AUTOSAR XML (schema 4-2-1)
package /MICROSAR/Dcm_swc
  mode declaration group DcmControlDtcSetting: category=EXPLICIT_ORDER, initial-mode=ENABLEDTCSETTING, on-transition-value=2
    mode ENABLEDTCSETTING: value=0
    mode DISABLEDTCSETTING: value=1
  mode declaration group DcmEcuReset: category=EXPLICIT_ORDER, initial-mode=NONE, on-transition-value=7
    7 x mode:
      NONE: value=0
      HARD: value=1
      KEYONOFF: value=2
      SOFT: value=3
      JUMPTOBOOTLOADER: value=4
      JUMPTOSYSSUPPLIERBOOTLOADER: value=5
      EXECUTE: value=6
  mode declaration group DcmDiagnosticSessionControl: category=EXPLICIT_ORDER, initial-mode=DEFAULT_SESSION, on-transition-value=255
    mode DEFAULT_SESSION: value=1
    mode PROGRAMMING_SESSION: value=2
    mode EXTENDED_SESSION: value=3
  data type mapping set DcmMappingSet  # Contains mapping for ModeDeclarationGroups which are provided by Dcm.
    mode-request-type-maps:
      implementation-data-type=Dcm_ControlDtcSettingType, mode-group=DcmControlDtcSetting
      implementation-data-type=Dcm_EcuResetType, mode-group=DcmEcuReset
      implementation-data-type=Dcm_DiagnosticSessionControlType, mode-group=DcmDiagnosticSessionControl
package /MICROSAR/Dcm_swc/DataTypes
  13 x impl type:
    Dcm_ConfirmationStatusType: compu {0=DCM_RES_POS_OK, 1=DCM_RES_POS_NOT_OK, 2=DCM_RES_NEG_OK, 3=DCM_RES_NEG_NOT_OK}, range raw 0..3, implementation-data-type=uint8
    Dcm_OpStatusType: compu {0=DCM_INITIAL, 1=DCM_PENDING, 2=DCM_CANCEL, 3=DCM_FORCE_RCRRP_OK, 64=DCM_FORCE_RCRRP_NOT_OK}, range raw 0..64, implementation-data-type=uint8
    Dcm_NegativeResponseCodeType:
      compu {0=DCM_E_POSITIVERESPONSE, 16=DCM_E_GENERALREJECT, 17=DCM_E_SERVICENOTSUPPORTED, 18=DCM_E_SUBFUNCTIONNOTSUPPORTED, 19=DCM_E_INCORRECTMESSAGELENGTHORINVALIDFORMAT, 20=DCM_E_RESPONSETOOLONG, 33=DCM_E_BUSYREPEATREQUEST, 34=DCM_E_CONDITIONSNOTCORRECT, 36=DCM_E_REQUESTSEQUENCEERROR, 37=DCM_E_NORESPONSEFROMSUBNETCOMPONENT, 38=DCM_E_FAILUREPREVENTSEXECUTIONOFREQUESTEDACTION, 49=DCM_E_REQUESTOUTOFRANGE, 51=DCM_E_SECURITYACCESSDENIED, 53=DCM_E_INVALIDKEY, 54=DCM_E_EXCEEDNUMBEROFATTEMPTS, 55=DCM_E_REQUIREDTIMEDELAYNOTEXPIRED, 112=DCM_E_UPLOADDOWNLOADNOTACCEPTED, 113=DCM_E_TRANSFERDATASUSPENDED, 114=DCM_E_GENERALPROGRAMMINGFAILURE, 115=DCM_E_WRONGBLOCKSEQUENCECOUNTER, 120=DCM_E_REQUESTCORRECTLYRECEIVEDRESPONSEPENDING, 126=DCM_E_SUBFUNCTIONNOTSUPPORTEDINACTIVESESSION, 127=DCM_E_SERVICENOTSUPPORTEDINACTIVESESSION, 129=DCM_E_RPMTOOHIGH, 130=DCM_E_RPMTOOLOW, 131=DCM_E_ENGINEISRUNNING, 132=DCM_E_ENGINEISNOTRUNNING, 133=DCM_E_ENGINERUNTIMETOOLOW, 134=DCM_E_TEMPERATURETOOHIGH, 135=DCM_E_TEMPERATURETOOLOW, 136=DCM_E_VEHICLESPEEDTOOHIGH, 137=DCM_E_VEHICLESPEEDTOOLOW, 138=DCM_E_THROTTLE_PEDALTOOHIGH, 139=DCM_E_THROTTLE_PEDALTOOLOW, 140=DCM_E_TRANSMISSIONRANGENOTINNEUTRAL, 141=DCM_E_TRANSMISSIONRANGENOTINGEAR, 143=DCM_E_BRAKESWITCH_NOTCLOSED, 144=DCM_E_SHIFTERLEVERNOTINPARK, 145=DCM_E_TORQUECONVERTERCLUTCHLOCKED, 146=DCM_E_VOLTAGETOOHIGH, 147=DCM_E_VOLTAGETOOLOW, 240..249=DCM_E_VMSCNC_0..DCM_E_VMSCNC_9, 250=DCM_E_VMSCNC_A, 251=DCM_E_VMSCNC_B, 252=DCM_E_VMSCNC_C, 253=DCM_E_VMSCNC_D, 254=DCM_E_VMSCNC_E}
      range raw 0..254
      implementation-data-type=uint8
    Dcm_ProtocolType: compu {0=DCM_OBD_ON_CAN, 1=DCM_OBD_ON_FLEXRAY, 2=DCM_OBD_ON_IP, 3=DCM_UDS_ON_CAN, 4=DCM_UDS_ON_FLEXRAY, 5=DCM_UDS_ON_IP, 12=DCM_NO_ACTIVE_PROTOCOL, 240..254=DCM_SUPPLIER_1..DCM_SUPPLIER_15}, range raw 0..254, implementation-data-type=uint8
    Dcm_RequestKindType: compu {0=DCM_REQ_KIND_NONE, 1=DCM_REQ_KIND_EXTERNAL, 2=DCM_REQ_KIND_ROE}, range raw 0..2, implementation-data-type=uint8
    Dcm_SesCtrlType: compu {1=DCM_DEFAULT_SESSION, 2=DCM_PROGRAMMING_SESSION, 3=DCM_EXTENDED_DIAGNOSTIC_SESSION}, range raw 0..3, implementation-data-type=uint8
    Dcm_ControlDtcSettingType: compu {0=DCM_ENUM_ENABLEDTCSETTING, 1=DCM_ENUM_DISABLEDTCSETTING}, range raw 0..255, implementation-data-type=uint8
    Dcm_EcuResetType: compu {0=DCM_ENUM_NONE, 1=DCM_ENUM_HARD, 2=DCM_ENUM_KEYONOFF, 3=DCM_ENUM_SOFT, 4=DCM_ENUM_JUMPTOBOOTLOADER, 5=DCM_ENUM_JUMPTOSYSSUPPLIERBOOTLOADER, 6=DCM_ENUM_EXECUTE}, range raw 0..255, implementation-data-type=uint8
    Dcm_DiagnosticSessionControlType: compu {1=DCM_ENUM_DEFAULT_SESSION, 2=DCM_ENUM_PROGRAMMING_SESSION, 3=DCM_ENUM_EXTENDED_SESSION}, range raw 0..255, implementation-data-type=uint8
    Dcm_CommunicationModeType:
      compu {0=DCM_ENABLE_RX_TX_NORM, 1=DCM_ENABLE_RX_DISABLE_TX_NORM, 2=DCM_DISABLE_RX_ENABLE_TX_NORM, 3=DCM_DISABLE_RX_TX_NORMAL, 4=DCM_ENABLE_RX_TX_NM, 5=DCM_ENABLE_RX_DISABLE_TX_NM, 6=DCM_DISABLE_RX_ENABLE_TX_NM, 7=DCM_DISABLE_RX_TX_NM, 8=DCM_ENABLE_RX_TX_NORM_NM, 9=DCM_ENABLE_RX_DISABLE_TX_NORM_NM, 10=DCM_DISABLE_RX_ENABLE_TX_NORM_NM, 11=DCM_DISABLE_RX_TX_NORM_NM}
      range raw 0..255
      implementation-data-type=uint8
    Dcm_Data2ByteType: category=ARRAY, sw-calibration-access=READ-ONLY
      element Dcm_Data2ByteTypeElement: array-size=2, array-size-semantics=FIXED-SIZE, implementation-data-type=uint8
    Dcm_Data4ByteType: category=ARRAY, sw-calibration-access=READ-ONLY
      element Dcm_Data4ByteTypeElement: array-size=4, array-size-semantics=FIXED-SIZE, implementation-data-type=uint8
    Dcm_SecLevelType: compu {0=DCM_SEC_LEV_LOCKED, 1=DCM_SEC_LEV_L1, 2=DCM_SEC_LEV_L2}, range raw 0..2, implementation-data-type=uint8
package /MICROSAR/Dcm_swc/Interfaces
  mode switch interface DcmControlDtcSetting: is-service=true, service-kind=DIAGNOSTIC-COMMUNICATION-MANAGER
    mode group DcmControlDtcSetting: type=DcmControlDtcSetting
  mode switch interface DcmEcuReset: is-service=true, service-kind=DIAGNOSTIC-COMMUNICATION-MANAGER
    mode group DcmEcuReset: type=DcmEcuReset
  mode switch interface DcmDiagnosticSessionControl: is-service=true, service-kind=DIAGNOSTIC-COMMUNICATION-MANAGER
    mode group DcmDiagnosticSessionControl: type=DcmDiagnosticSessionControl
  26 x client server interface, all with is-service=true, service-kind=DIAGNOSTIC-COMMUNICATION-MANAGER:
    DCMServices
      6 x operation:
        GetActiveProtocol: possible-error=E_OK
          arg ActiveProtocol: type=Dcm_ProtocolType, direction=OUT
        GetSesCtrlType: possible-error=E_OK
          arg SesCtrlType: type=Dcm_SesCtrlType, direction=OUT
        ResetToDefaultSession: possible-error=E_OK
        GetSecurityLevel: possible-error=E_OK
          arg SecLevel: type=Dcm_SecLevelType, direction=OUT
        SetActiveDiagnostic: possible-error=E_OK
          arg active: type=boolean, direction=IN
        GetRequestKind: possible-error=DCMServices/E_NOT_OK
          arg TesterSourceAddress: type=uint16, direction=IN
          arg RequestKind: type=Dcm_RequestKindType, direction=OUT
      error E_OK: error-code=0
      error E_NOT_OK: error-code=1
    SecurityAccess_Level_01
      operation GetSeed: possible-error=[SecurityAccess_Level_01/E_NOT_OK, SecurityAccess_Level_01/DCM_E_PENDING]
        arg OpStatus: type=Dcm_OpStatusType, direction=IN
        arg Seed: type=Dcm_Data2ByteType, direction=OUT
        arg ErrorCode: type=Dcm_NegativeResponseCodeType, direction=OUT
      operation CompareKey: possible-error=[SecurityAccess_Level_01/E_NOT_OK, SecurityAccess_Level_01/DCM_E_PENDING, SecurityAccess_Level_01/DCM_E_COMPARE_KEY_FAILED]
        arg Key: type=Dcm_Data2ByteType, direction=IN
        arg OpStatus: type=Dcm_OpStatusType, direction=IN
        arg ErrorCode: type=Dcm_NegativeResponseCodeType, direction=OUT
      error E_NOT_OK: error-code=1
      error DCM_E_PENDING: error-code=10
      error DCM_E_COMPARE_KEY_FAILED: error-code=11
    DataServices_Diag_RWDI_LightOnOffCounter_LightOnOffCounter_Value
      operation ReadData: possible-error=[DataServices_Diag_RWDI_LightOnOffCounter_LightOnOffCounter_Value/E_NOT_OK, DataServices_Diag_RWDI_LightOnOffCounter_LightOnOffCounter_Value/DCM_E_PENDING]
        arg OpStatus: type=Dcm_OpStatusType, direction=IN
        arg Data: type=Dcm_Data4ByteType, direction=OUT
      operation ConditionCheckRead: possible-error=[DataServices_Diag_RWDI_LightOnOffCounter_LightOnOffCounter_Value/E_NOT_OK, DataServices_Diag_RWDI_LightOnOffCounter_LightOnOffCounter_Value/DCM_E_PENDING]
        arg OpStatus: type=Dcm_OpStatusType, direction=IN
        arg ErrorCode: type=Dcm_NegativeResponseCodeType, direction=OUT
      operation WriteData: possible-error=[DataServices_Diag_RWDI_LightOnOffCounter_LightOnOffCounter_Value/E_NOT_OK, DataServices_Diag_RWDI_LightOnOffCounter_LightOnOffCounter_Value/DCM_E_PENDING]
        arg Data: type=Dcm_Data4ByteType, direction=IN
        arg OpStatus: type=Dcm_OpStatusType, direction=IN
        arg ErrorCode: type=Dcm_NegativeResponseCodeType, direction=OUT
      error E_NOT_OK: error-code=1
      error DCM_E_PENDING: error-code=10
    DataServices_Diag_VM_HardwarePartNumber
      operation ReadData: possible-error=[DataServices_Diag_VM_HardwarePartNumber/E_NOT_OK, DataServices_Diag_VM_HardwarePartNumber/DCM_E_PENDING]
        arg OpStatus: type=Dcm_OpStatusType, direction=IN
        arg Data: type=Dcm_Data4ByteType, direction=OUT
      operation ConditionCheckRead: possible-error=[DataServices_Diag_VM_HardwarePartNumber/E_NOT_OK, DataServices_Diag_VM_HardwarePartNumber/DCM_E_PENDING]
        arg OpStatus: type=Dcm_OpStatusType, direction=IN
        arg ErrorCode: type=Dcm_NegativeResponseCodeType, direction=OUT
      operation WriteData: possible-error=[DataServices_Diag_VM_HardwarePartNumber/E_NOT_OK, DataServices_Diag_VM_HardwarePartNumber/DCM_E_PENDING]
        arg Data: type=Dcm_Data4ByteType, direction=IN
        arg OpStatus: type=Dcm_OpStatusType, direction=IN
        arg ErrorCode: type=Dcm_NegativeResponseCodeType, direction=OUT
      error E_NOT_OK: error-code=1
      error DCM_E_PENDING: error-code=10
    DataServices_Diag_VM_HardwareBaseline
      operation ReadData: possible-error=[DataServices_Diag_VM_HardwareBaseline/E_NOT_OK, DataServices_Diag_VM_HardwareBaseline/DCM_E_PENDING]
        arg OpStatus: type=Dcm_OpStatusType, direction=IN
        arg Data: type=Dcm_Data4ByteType, direction=OUT
      operation ConditionCheckRead: possible-error=[DataServices_Diag_VM_HardwareBaseline/E_NOT_OK, DataServices_Diag_VM_HardwareBaseline/DCM_E_PENDING]
        arg OpStatus: type=Dcm_OpStatusType, direction=IN
        arg ErrorCode: type=Dcm_NegativeResponseCodeType, direction=OUT
      operation WriteData: possible-error=[DataServices_Diag_VM_HardwareBaseline/E_NOT_OK, DataServices_Diag_VM_HardwareBaseline/DCM_E_PENDING]
        arg Data: type=Dcm_Data4ByteType, direction=IN
        arg OpStatus: type=Dcm_OpStatusType, direction=IN
        arg ErrorCode: type=Dcm_NegativeResponseCodeType, direction=OUT
      error E_NOT_OK: error-code=1
      error DCM_E_PENDING: error-code=10
    DataServices_DcmDspData_VM_SofwarePartNumber
      operation ReadData: possible-error=[DataServices_DcmDspData_VM_SofwarePartNumber/E_NOT_OK, DataServices_DcmDspData_VM_SofwarePartNumber/DCM_E_PENDING]
        arg OpStatus: type=Dcm_OpStatusType, direction=IN
        arg Data: type=Dcm_Data4ByteType, direction=OUT
      operation ConditionCheckRead: possible-error=[DataServices_DcmDspData_VM_SofwarePartNumber/E_NOT_OK, DataServices_DcmDspData_VM_SofwarePartNumber/DCM_E_PENDING]
        arg OpStatus: type=Dcm_OpStatusType, direction=IN
        arg ErrorCode: type=Dcm_NegativeResponseCodeType, direction=OUT
      operation WriteData: possible-error=[DataServices_DcmDspData_VM_SofwarePartNumber/E_NOT_OK, DataServices_DcmDspData_VM_SofwarePartNumber/DCM_E_PENDING]
        arg Data: type=Dcm_Data4ByteType, direction=IN
        arg OpStatus: type=Dcm_OpStatusType, direction=IN
        arg ErrorCode: type=Dcm_NegativeResponseCodeType, direction=OUT
      error E_NOT_OK: error-code=1
      error DCM_E_PENDING: error-code=10
    DataServices_DcmDspData_VM_SoftwarBaseline
      operation ReadData: possible-error=[DataServices_DcmDspData_VM_SoftwarBaseline/E_NOT_OK, DataServices_DcmDspData_VM_SoftwarBaseline/DCM_E_PENDING]
        arg OpStatus: type=Dcm_OpStatusType, direction=IN
        arg Data: type=Dcm_Data4ByteType, direction=OUT
      operation ConditionCheckRead: possible-error=[DataServices_DcmDspData_VM_SoftwarBaseline/E_NOT_OK, DataServices_DcmDspData_VM_SoftwarBaseline/DCM_E_PENDING]
        arg OpStatus: type=Dcm_OpStatusType, direction=IN
        arg ErrorCode: type=Dcm_NegativeResponseCodeType, direction=OUT
      operation WriteData: possible-error=[DataServices_DcmDspData_VM_SoftwarBaseline/E_NOT_OK, DataServices_DcmDspData_VM_SoftwarBaseline/DCM_E_PENDING]
        arg Data: type=Dcm_Data4ByteType, direction=IN
        arg OpStatus: type=Dcm_OpStatusType, direction=IN
        arg ErrorCode: type=Dcm_NegativeResponseCodeType, direction=OUT
      error E_NOT_OK: error-code=1
      error DCM_E_PENDING: error-code=10
    DataServices_DcmDspData_VM_FOTASpecialPartNumber
      operation ReadData: possible-error=[DataServices_DcmDspData_VM_FOTASpecialPartNumber/E_NOT_OK, DataServices_DcmDspData_VM_FOTASpecialPartNumber/DCM_E_PENDING]
        arg OpStatus: type=Dcm_OpStatusType, direction=IN
        arg Data: type=Dcm_Data4ByteType, direction=OUT
      operation ConditionCheckRead: possible-error=[DataServices_DcmDspData_VM_FOTASpecialPartNumber/E_NOT_OK, DataServices_DcmDspData_VM_FOTASpecialPartNumber/DCM_E_PENDING]
        arg OpStatus: type=Dcm_OpStatusType, direction=IN
        arg ErrorCode: type=Dcm_NegativeResponseCodeType, direction=OUT
      operation WriteData: possible-error=[DataServices_DcmDspData_VM_FOTASpecialPartNumber/E_NOT_OK, DataServices_DcmDspData_VM_FOTASpecialPartNumber/DCM_E_PENDING]
        arg Data: type=Dcm_Data4ByteType, direction=IN
        arg OpStatus: type=Dcm_OpStatusType, direction=IN
        arg ErrorCode: type=Dcm_NegativeResponseCodeType, direction=OUT
      error E_NOT_OK: error-code=1
      error DCM_E_PENDING: error-code=10
    DataServices_DcmDspData_VM_CalibrarionPartNumber
      operation ReadData: possible-error=[DataServices_DcmDspData_VM_CalibrarionPartNumber/E_NOT_OK, DataServices_DcmDspData_VM_CalibrarionPartNumber/DCM_E_PENDING]
        arg OpStatus: type=Dcm_OpStatusType, direction=IN
        arg Data: type=Dcm_Data4ByteType, direction=OUT
      operation ConditionCheckRead: possible-error=[DataServices_DcmDspData_VM_CalibrarionPartNumber/E_NOT_OK, DataServices_DcmDspData_VM_CalibrarionPartNumber/DCM_E_PENDING]
        arg OpStatus: type=Dcm_OpStatusType, direction=IN
        arg ErrorCode: type=Dcm_NegativeResponseCodeType, direction=OUT
      operation WriteData: possible-error=[DataServices_DcmDspData_VM_CalibrarionPartNumber/E_NOT_OK, DataServices_DcmDspData_VM_CalibrarionPartNumber/DCM_E_PENDING]
        arg Data: type=Dcm_Data4ByteType, direction=IN
        arg OpStatus: type=Dcm_OpStatusType, direction=IN
        arg ErrorCode: type=Dcm_NegativeResponseCodeType, direction=OUT
      error E_NOT_OK: error-code=1
      error DCM_E_PENDING: error-code=10
    DataServices_DcmDspData_VM_CalibrationBaseline
      operation ReadData: possible-error=[DataServices_DcmDspData_VM_CalibrationBaseline/E_NOT_OK, DataServices_DcmDspData_VM_CalibrationBaseline/DCM_E_PENDING]
        arg OpStatus: type=Dcm_OpStatusType, direction=IN
        arg Data: type=Dcm_Data4ByteType, direction=OUT
      operation ConditionCheckRead: possible-error=[DataServices_DcmDspData_VM_CalibrationBaseline/E_NOT_OK, DataServices_DcmDspData_VM_CalibrationBaseline/DCM_E_PENDING]
        arg OpStatus: type=Dcm_OpStatusType, direction=IN
        arg ErrorCode: type=Dcm_NegativeResponseCodeType, direction=OUT
      operation WriteData: possible-error=[DataServices_DcmDspData_VM_CalibrationBaseline/E_NOT_OK, DataServices_DcmDspData_VM_CalibrationBaseline/DCM_E_PENDING]
        arg Data: type=Dcm_Data4ByteType, direction=IN
        arg OpStatus: type=Dcm_OpStatusType, direction=IN
        arg ErrorCode: type=Dcm_NegativeResponseCodeType, direction=OUT
      error E_NOT_OK: error-code=1
      error DCM_E_PENDING: error-code=10
    DataServices_DcmDspData_VM_Specialdatabaseline
      4 x operation, all with possible-error=[DataServices_DcmDspData_VM_Specialdatabaseline/E_NOT_OK, DataServices_DcmDspData_VM_Specialdatabaseline/DCM_E_PENDING]:
        ReadData
          arg OpStatus: type=Dcm_OpStatusType, direction=IN
          arg Data: type=Dcm_Data4ByteType, direction=OUT
        ReadDataLength
          arg OpStatus: type=Dcm_OpStatusType, direction=IN
          arg DataLength: type=uint16, direction=OUT
        ConditionCheckRead
          arg OpStatus: type=Dcm_OpStatusType, direction=IN
          arg ErrorCode: type=Dcm_NegativeResponseCodeType, direction=OUT
        WriteData
          4 x arg:
            Data: type=Dcm_Data4ByteType, direction=IN
            DataLength: type=uint16, direction=IN
            OpStatus: type=Dcm_OpStatusType, direction=IN
            ErrorCode: type=Dcm_NegativeResponseCodeType, direction=OUT
      error E_NOT_OK: error-code=1
      error DCM_E_PENDING: error-code=10
    DataServices_DcmDspData_ReadFingerprint
      operation ReadData: possible-error=[DataServices_DcmDspData_ReadFingerprint/E_NOT_OK, DataServices_DcmDspData_ReadFingerprint/DCM_E_PENDING]
        arg OpStatus: type=Dcm_OpStatusType, direction=IN
        arg Data: type=Dcm_Data4ByteType, direction=OUT
      operation ConditionCheckRead: possible-error=[DataServices_DcmDspData_ReadFingerprint/E_NOT_OK, DataServices_DcmDspData_ReadFingerprint/DCM_E_PENDING]
        arg OpStatus: type=Dcm_OpStatusType, direction=IN
        arg ErrorCode: type=Dcm_NegativeResponseCodeType, direction=OUT
      error E_NOT_OK: error-code=1
      error DCM_E_PENDING: error-code=10
    DataServices_DcmDspData_ReadActiveDiagSession
      operation ReadData: possible-error=[DataServices_DcmDspData_ReadActiveDiagSession/E_NOT_OK, DataServices_DcmDspData_ReadActiveDiagSession/DCM_E_PENDING]
        arg OpStatus: type=Dcm_OpStatusType, direction=IN
        arg Data: type=Dcm_Data4ByteType, direction=OUT
      operation ConditionCheckRead: possible-error=[DataServices_DcmDspData_ReadActiveDiagSession/E_NOT_OK, DataServices_DcmDspData_ReadActiveDiagSession/DCM_E_PENDING]
        arg OpStatus: type=Dcm_OpStatusType, direction=IN
        arg ErrorCode: type=Dcm_NegativeResponseCodeType, direction=OUT
      error E_NOT_OK: error-code=1
      error DCM_E_PENDING: error-code=10
    DataServices_DcmDspData_VM_SparepartNumber
      operation ReadData: possible-error=[DataServices_DcmDspData_VM_SparepartNumber/E_NOT_OK, DataServices_DcmDspData_VM_SparepartNumber/DCM_E_PENDING]
        arg OpStatus: type=Dcm_OpStatusType, direction=IN
        arg Data: type=Dcm_Data4ByteType, direction=OUT
      operation ConditionCheckRead: possible-error=[DataServices_DcmDspData_VM_SparepartNumber/E_NOT_OK, DataServices_DcmDspData_VM_SparepartNumber/DCM_E_PENDING]
        arg OpStatus: type=Dcm_OpStatusType, direction=IN
        arg ErrorCode: type=Dcm_NegativeResponseCodeType, direction=OUT
      operation WriteData: possible-error=[DataServices_DcmDspData_VM_SparepartNumber/E_NOT_OK, DataServices_DcmDspData_VM_SparepartNumber/DCM_E_PENDING]
        arg Data: type=Dcm_Data4ByteType, direction=IN
        arg OpStatus: type=Dcm_OpStatusType, direction=IN
        arg ErrorCode: type=Dcm_NegativeResponseCodeType, direction=OUT
      error E_NOT_OK: error-code=1
      error DCM_E_PENDING: error-code=10
    DataServices_DcmDspData_ECUDiagDatabaseVersion
      operation ReadData: possible-error=[DataServices_DcmDspData_ECUDiagDatabaseVersion/E_NOT_OK, DataServices_DcmDspData_ECUDiagDatabaseVersion/DCM_E_PENDING]
        arg OpStatus: type=Dcm_OpStatusType, direction=IN
        arg Data: type=Dcm_Data4ByteType, direction=OUT
      operation ConditionCheckRead: possible-error=[DataServices_DcmDspData_ECUDiagDatabaseVersion/E_NOT_OK, DataServices_DcmDspData_ECUDiagDatabaseVersion/DCM_E_PENDING]
        arg OpStatus: type=Dcm_OpStatusType, direction=IN
        arg ErrorCode: type=Dcm_NegativeResponseCodeType, direction=OUT
      operation WriteData: possible-error=[DataServices_DcmDspData_ECUDiagDatabaseVersion/E_NOT_OK, DataServices_DcmDspData_ECUDiagDatabaseVersion/DCM_E_PENDING]
        arg Data: type=Dcm_Data4ByteType, direction=IN
        arg OpStatus: type=Dcm_OpStatusType, direction=IN
        arg ErrorCode: type=Dcm_NegativeResponseCodeType, direction=OUT
      error E_NOT_OK: error-code=1
      error DCM_E_PENDING: error-code=10
    DataServices_DcmDspData_BootloaderVersion
      operation ReadData: possible-error=[DataServices_DcmDspData_BootloaderVersion/E_NOT_OK, DataServices_DcmDspData_BootloaderVersion/DCM_E_PENDING]
        arg OpStatus: type=Dcm_OpStatusType, direction=IN
        arg Data: type=Dcm_Data4ByteType, direction=OUT
      operation ReadDataLength: possible-error=[DataServices_DcmDspData_BootloaderVersion/E_NOT_OK, DataServices_DcmDspData_BootloaderVersion/DCM_E_PENDING]
        arg OpStatus: type=Dcm_OpStatusType, direction=IN
        arg DataLength: type=uint16, direction=OUT
      operation ConditionCheckRead: possible-error=[DataServices_DcmDspData_BootloaderVersion/E_NOT_OK, DataServices_DcmDspData_BootloaderVersion/DCM_E_PENDING]
        arg OpStatus: type=Dcm_OpStatusType, direction=IN
        arg ErrorCode: type=Dcm_NegativeResponseCodeType, direction=OUT
      error E_NOT_OK: error-code=1
      error DCM_E_PENDING: error-code=10
    DataServices_DcmDspData_SystemSupplierIdData
      operation ReadData: possible-error=[DataServices_DcmDspData_SystemSupplierIdData/E_NOT_OK, DataServices_DcmDspData_SystemSupplierIdData/DCM_E_PENDING]
        arg OpStatus: type=Dcm_OpStatusType, direction=IN
        arg Data: type=Dcm_Data4ByteType, direction=OUT
      operation ConditionCheckRead: possible-error=[DataServices_DcmDspData_SystemSupplierIdData/E_NOT_OK, DataServices_DcmDspData_SystemSupplierIdData/DCM_E_PENDING]
        arg OpStatus: type=Dcm_OpStatusType, direction=IN
        arg ErrorCode: type=Dcm_NegativeResponseCodeType, direction=OUT
      error E_NOT_OK: error-code=1
      error DCM_E_PENDING: error-code=10
    DataServices_DcmDspData_ECUManufacturingDate
      operation ReadData: possible-error=[DataServices_DcmDspData_ECUManufacturingDate/E_NOT_OK, DataServices_DcmDspData_ECUManufacturingDate/DCM_E_PENDING]
        arg OpStatus: type=Dcm_OpStatusType, direction=IN
        arg Data: type=Dcm_Data4ByteType, direction=OUT
      operation ConditionCheckRead: possible-error=[DataServices_DcmDspData_ECUManufacturingDate/E_NOT_OK, DataServices_DcmDspData_ECUManufacturingDate/DCM_E_PENDING]
        arg OpStatus: type=Dcm_OpStatusType, direction=IN
        arg ErrorCode: type=Dcm_NegativeResponseCodeType, direction=OUT
      error E_NOT_OK: error-code=1
      error DCM_E_PENDING: error-code=10
    DataServices_DcmDspData_ECUSerialNumber
      operation ReadData: possible-error=[DataServices_DcmDspData_ECUSerialNumber/E_NOT_OK, DataServices_DcmDspData_ECUSerialNumber/DCM_E_PENDING]
        arg OpStatus: type=Dcm_OpStatusType, direction=IN
        arg Data: type=Dcm_Data4ByteType, direction=OUT
      operation ConditionCheckRead: possible-error=[DataServices_DcmDspData_ECUSerialNumber/E_NOT_OK, DataServices_DcmDspData_ECUSerialNumber/DCM_E_PENDING]
        arg OpStatus: type=Dcm_OpStatusType, direction=IN
        arg ErrorCode: type=Dcm_NegativeResponseCodeType, direction=OUT
      error E_NOT_OK: error-code=1
      error DCM_E_PENDING: error-code=10
    DataServices_DcmDspData_VIN
      operation ReadData: possible-error=[DataServices_DcmDspData_VIN/E_NOT_OK, DataServices_DcmDspData_VIN/DCM_E_PENDING]
        arg OpStatus: type=Dcm_OpStatusType, direction=IN
        arg Data: type=Dcm_Data4ByteType, direction=OUT
      operation ConditionCheckRead: possible-error=[DataServices_DcmDspData_VIN/E_NOT_OK, DataServices_DcmDspData_VIN/DCM_E_PENDING]
        arg OpStatus: type=Dcm_OpStatusType, direction=IN
        arg ErrorCode: type=Dcm_NegativeResponseCodeType, direction=OUT
      operation WriteData: possible-error=[DataServices_DcmDspData_VIN/E_NOT_OK, DataServices_DcmDspData_VIN/DCM_E_PENDING]
        arg Data: type=Dcm_Data4ByteType, direction=IN
        arg OpStatus: type=Dcm_OpStatusType, direction=IN
        arg ErrorCode: type=Dcm_NegativeResponseCodeType, direction=OUT
      error E_NOT_OK: error-code=1
      error DCM_E_PENDING: error-code=10
    DataServices_DcmDspData_SystemName
      operation ReadData: possible-error=[DataServices_DcmDspData_SystemName/E_NOT_OK, DataServices_DcmDspData_SystemName/DCM_E_PENDING]
        arg OpStatus: type=Dcm_OpStatusType, direction=IN
        arg Data: type=Dcm_Data4ByteType, direction=OUT
      operation ReadDataLength: possible-error=[DataServices_DcmDspData_SystemName/E_NOT_OK, DataServices_DcmDspData_SystemName/DCM_E_PENDING]
        arg OpStatus: type=Dcm_OpStatusType, direction=IN
        arg DataLength: type=uint16, direction=OUT
      operation ConditionCheckRead: possible-error=[DataServices_DcmDspData_SystemName/E_NOT_OK, DataServices_DcmDspData_SystemName/DCM_E_PENDING]
        arg OpStatus: type=Dcm_OpStatusType, direction=IN
        arg ErrorCode: type=Dcm_NegativeResponseCodeType, direction=OUT
      error E_NOT_OK: error-code=1
      error DCM_E_PENDING: error-code=10
    DataServices_DcmDspData_RepairShopFingerPrint
      operation ReadData: possible-error=[DataServices_DcmDspData_RepairShopFingerPrint/E_NOT_OK, DataServices_DcmDspData_RepairShopFingerPrint/DCM_E_PENDING]
        arg OpStatus: type=Dcm_OpStatusType, direction=IN
        arg Data: type=Dcm_Data4ByteType, direction=OUT
      operation ConditionCheckRead: possible-error=[DataServices_DcmDspData_RepairShopFingerPrint/E_NOT_OK, DataServices_DcmDspData_RepairShopFingerPrint/DCM_E_PENDING]
        arg OpStatus: type=Dcm_OpStatusType, direction=IN
        arg ErrorCode: type=Dcm_NegativeResponseCodeType, direction=OUT
      operation WriteData: possible-error=[DataServices_DcmDspData_RepairShopFingerPrint/E_NOT_OK, DataServices_DcmDspData_RepairShopFingerPrint/DCM_E_PENDING]
        arg Data: type=Dcm_Data4ByteType, direction=IN
        arg OpStatus: type=Dcm_OpStatusType, direction=IN
        arg ErrorCode: type=Dcm_NegativeResponseCodeType, direction=OUT
      error E_NOT_OK: error-code=1
      error DCM_E_PENDING: error-code=10
    DataServices_DcmDspData_ECUProgrammingDate
      operation ReadData: possible-error=[DataServices_DcmDspData_ECUProgrammingDate/E_NOT_OK, DataServices_DcmDspData_ECUProgrammingDate/DCM_E_PENDING]
        arg OpStatus: type=Dcm_OpStatusType, direction=IN
        arg Data: type=Dcm_Data4ByteType, direction=OUT
      operation ConditionCheckRead: possible-error=[DataServices_DcmDspData_ECUProgrammingDate/E_NOT_OK, DataServices_DcmDspData_ECUProgrammingDate/DCM_E_PENDING]
        arg OpStatus: type=Dcm_OpStatusType, direction=IN
        arg ErrorCode: type=Dcm_NegativeResponseCodeType, direction=OUT
      error E_NOT_OK: error-code=1
      error DCM_E_PENDING: error-code=10
    DataServices_DcmDspData_ECUConfigurarion
      operation ReadData: possible-error=[DataServices_DcmDspData_ECUConfigurarion/E_NOT_OK, DataServices_DcmDspData_ECUConfigurarion/DCM_E_PENDING]
        arg OpStatus: type=Dcm_OpStatusType, direction=IN
        arg Data: type=Dcm_Data4ByteType, direction=OUT
      operation ConditionCheckRead: possible-error=[DataServices_DcmDspData_ECUConfigurarion/E_NOT_OK, DataServices_DcmDspData_ECUConfigurarion/DCM_E_PENDING]
        arg OpStatus: type=Dcm_OpStatusType, direction=IN
        arg ErrorCode: type=Dcm_NegativeResponseCodeType, direction=OUT
      operation WriteData: possible-error=[DataServices_DcmDspData_ECUConfigurarion/E_NOT_OK, DataServices_DcmDspData_ECUConfigurarion/DCM_E_PENDING]
        arg Data: type=Dcm_Data4ByteType, direction=IN
        arg OpStatus: type=Dcm_OpStatusType, direction=IN
        arg ErrorCode: type=Dcm_NegativeResponseCodeType, direction=OUT
      error E_NOT_OK: error-code=1
      error DCM_E_PENDING: error-code=10
    DataServices_DcmDspData_ConfigurarionFingerprint
      operation ReadData: possible-error=[DataServices_DcmDspData_ConfigurarionFingerprint/E_NOT_OK, DataServices_DcmDspData_ConfigurarionFingerprint/DCM_E_PENDING]
        arg OpStatus: type=Dcm_OpStatusType, direction=IN
        arg Data: type=Dcm_Data4ByteType, direction=OUT
      operation ConditionCheckRead: possible-error=[DataServices_DcmDspData_ConfigurarionFingerprint/E_NOT_OK, DataServices_DcmDspData_ConfigurarionFingerprint/DCM_E_PENDING]
        arg OpStatus: type=Dcm_OpStatusType, direction=IN
        arg ErrorCode: type=Dcm_NegativeResponseCodeType, direction=OUT
      operation WriteData: possible-error=[DataServices_DcmDspData_ConfigurarionFingerprint/E_NOT_OK, DataServices_DcmDspData_ConfigurarionFingerprint/DCM_E_PENDING]
        arg Data: type=Dcm_Data4ByteType, direction=IN
        arg OpStatus: type=Dcm_OpStatusType, direction=IN
        arg ErrorCode: type=Dcm_NegativeResponseCodeType, direction=OUT
      error E_NOT_OK: error-code=1
      error DCM_E_PENDING: error-code=10
    SecurityAccess_Level_02
      operation GetSeed: possible-error=[SecurityAccess_Level_02/E_NOT_OK, SecurityAccess_Level_02/DCM_E_PENDING]
        arg OpStatus: type=Dcm_OpStatusType, direction=IN
        arg Seed: type=Dcm_Data4ByteType, direction=OUT
        arg ErrorCode: type=Dcm_NegativeResponseCodeType, direction=OUT
      operation CompareKey: possible-error=[SecurityAccess_Level_02/E_NOT_OK, SecurityAccess_Level_02/DCM_E_PENDING, SecurityAccess_Level_02/DCM_E_COMPARE_KEY_FAILED]
        arg Key: type=Dcm_Data4ByteType, direction=IN
        arg OpStatus: type=Dcm_OpStatusType, direction=IN
        arg ErrorCode: type=Dcm_NegativeResponseCodeType, direction=OUT
      error E_NOT_OK: error-code=1
      error DCM_E_PENDING: error-code=10
      error DCM_E_COMPARE_KEY_FAILED: error-code=11
package /MICROSAR/Dcm_swc/ComponentTypes
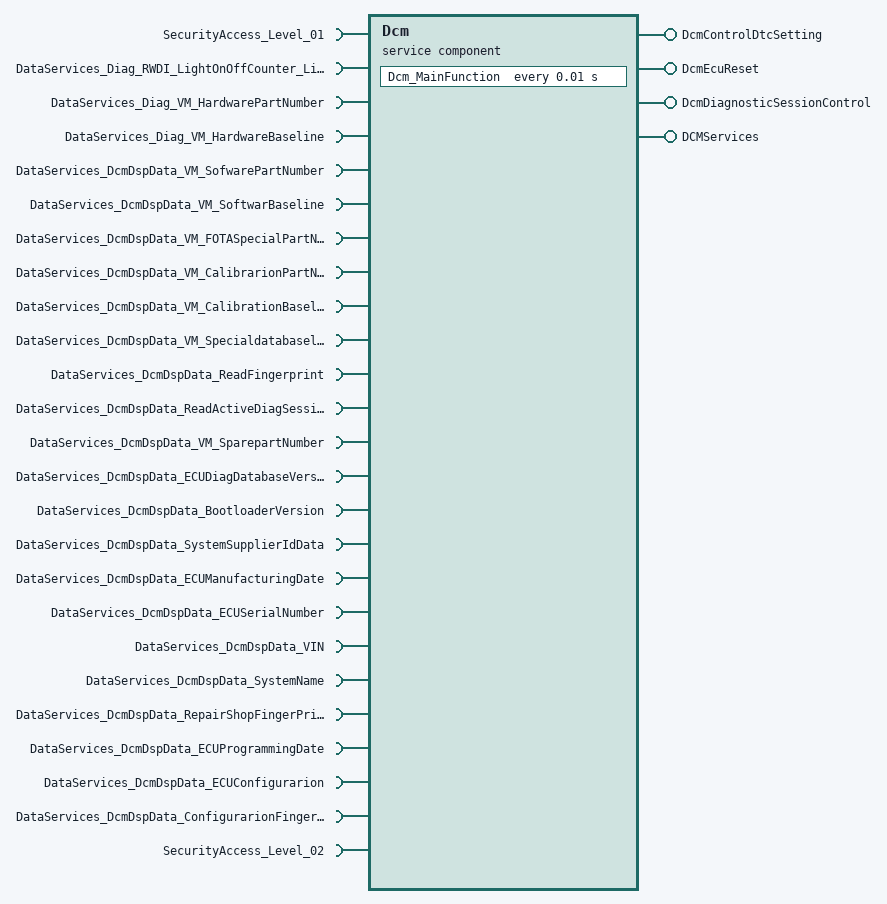
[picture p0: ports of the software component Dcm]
  service sw component type Dcm: category=SERVICE_COMPONENT
    4 x provide port:
      DcmControlDtcSetting: provided-interface=DcmControlDtcSetting
      DcmEcuReset: mode-switch-sender-com-spec{mode-group=DcmEcuReset, mode-switched-ack=timeout=0}, provided-interface=DcmEcuReset
      DcmDiagnosticSessionControl: provided-interface=DcmDiagnosticSessionControl
      DCMServices: provided-interface=DCMServices
    25 x require port:
      SecurityAccess_Level_01: required-interface=SecurityAccess_Level_01
      DataServices_Diag_RWDI_LightOnOffCounter_LightOnOffCounter_Value: required-interface=DataServices_Diag_RWDI_LightOnOffCounter_LightOnOffCounter_Value
      DataServices_Diag_VM_HardwarePartNumber: required-interface=DataServices_Diag_VM_HardwarePartNumber
      DataServices_Diag_VM_HardwareBaseline: required-interface=DataServices_Diag_VM_HardwareBaseline
      DataServices_DcmDspData_VM_SofwarePartNumber: required-interface=DataServices_DcmDspData_VM_SofwarePartNumber
      DataServices_DcmDspData_VM_SoftwarBaseline: required-interface=DataServices_DcmDspData_VM_SoftwarBaseline
      DataServices_DcmDspData_VM_FOTASpecialPartNumber: required-interface=DataServices_DcmDspData_VM_FOTASpecialPartNumber
      DataServices_DcmDspData_VM_CalibrarionPartNumber: required-interface=DataServices_DcmDspData_VM_CalibrarionPartNumber
      DataServices_DcmDspData_VM_CalibrationBaseline: required-interface=DataServices_DcmDspData_VM_CalibrationBaseline
      DataServices_DcmDspData_VM_Specialdatabaseline: required-interface=DataServices_DcmDspData_VM_Specialdatabaseline
      DataServices_DcmDspData_ReadFingerprint: required-interface=DataServices_DcmDspData_ReadFingerprint
      DataServices_DcmDspData_ReadActiveDiagSession: required-interface=DataServices_DcmDspData_ReadActiveDiagSession
      DataServices_DcmDspData_VM_SparepartNumber: required-interface=DataServices_DcmDspData_VM_SparepartNumber
      DataServices_DcmDspData_ECUDiagDatabaseVersion: required-interface=DataServices_DcmDspData_ECUDiagDatabaseVersion
      DataServices_DcmDspData_BootloaderVersion: required-interface=DataServices_DcmDspData_BootloaderVersion
      DataServices_DcmDspData_SystemSupplierIdData: required-interface=DataServices_DcmDspData_SystemSupplierIdData
      DataServices_DcmDspData_ECUManufacturingDate: required-interface=DataServices_DcmDspData_ECUManufacturingDate
      DataServices_DcmDspData_ECUSerialNumber: required-interface=DataServices_DcmDspData_ECUSerialNumber
      DataServices_DcmDspData_VIN: required-interface=DataServices_DcmDspData_VIN
      DataServices_DcmDspData_SystemName: required-interface=DataServices_DcmDspData_SystemName
      DataServices_DcmDspData_RepairShopFingerPrint: required-interface=DataServices_DcmDspData_RepairShopFingerPrint
      DataServices_DcmDspData_ECUProgrammingDate: required-interface=DataServices_DcmDspData_ECUProgrammingDate
      DataServices_DcmDspData_ECUConfigurarion: required-interface=DataServices_DcmDspData_ECUConfigurarion
      DataServices_DcmDspData_ConfigurarionFingerprint: required-interface=DataServices_DcmDspData_ConfigurarionFingerprint
      SecurityAccess_Level_02: required-interface=SecurityAccess_Level_02
    behavior DcmInternalBehavior: data-type-mapping=DcmMappingSet, handle-termination-and-restart=NO-SUPPORT, included-data-type-set=data-type=[Dcm_ConfirmationStatusType, Dcm_OpStatusType, Dcm_NegativeResponseCodeType, Dcm_ProtocolType, Dcm_RequestKindType, Dcm_SecLevelType, Dcm_SesCtrlType, Dcm_ControlDtcSettingType, Dcm_EcuResetType, Dcm_DiagnosticSessionControlType, Dcm_CommunicationModeType]
      timing event Timer_Dcm_MainFunction: start-on-event=Dcm_MainFunction, period=0.01
      6 x operation invoked event:
        OpEventGetActiveProtocol_GetActiveProtocol_DCMServices: start-on-event=GetActiveProtocol, operation=DCMServices.GetActiveProtocol
        OpEventGetSesCtrlType_GetSesCtrlType_DCMServices: start-on-event=GetSesCtrlType, operation=DCMServices.GetSesCtrlType
        OpEventResetToDefaultSession_ResetToDefaultSession_DCMServices: start-on-event=ResetToDefaultSession, operation=DCMServices.ResetToDefaultSession
        OpEventGetSecurityLevel_GetSecurityLevel_DCMServices: start-on-event=GetSecurityLevel, operation=DCMServices.GetSecurityLevel
        OpEventSetActiveDiagnostic_SetActiveDiagnostic_DCMServices: start-on-event=SetActiveDiagnostic, operation=DCMServices.SetActiveDiagnostic
        OpEventGetRequestKind_GetRequestKind_DCMServices: start-on-event=GetRequestKind, operation=DCMServices.GetRequestKind
      port-api-options:
        enable-take-address=true, indirect-api=false, port=DcmControlDtcSetting
        enable-take-address=true, indirect-api=false, port=DcmEcuReset
        enable-take-address=true, indirect-api=false, port=DcmDiagnosticSessionControl
        enable-take-address=true, indirect-api=false, port=DCMServices
        enable-take-address=true, indirect-api=false, port=SecurityAccess_Level_01
        enable-take-address=true, indirect-api=false, port=DataServices_Diag_RWDI_LightOnOffCounter_LightOnOffCounter_Value
        enable-take-address=true, indirect-api=false, port=DataServices_Diag_VM_HardwarePartNumber
        enable-take-address=true, indirect-api=false, port=DataServices_Diag_VM_HardwareBaseline
        enable-take-address=true, indirect-api=false, port=DataServices_DcmDspData_VM_SofwarePartNumber
        enable-take-address=true, indirect-api=false, port=DataServices_DcmDspData_VM_SoftwarBaseline
        enable-take-address=true, indirect-api=false, port=DataServices_DcmDspData_VM_FOTASpecialPartNumber
        enable-take-address=true, indirect-api=false, port=DataServices_DcmDspData_VM_CalibrarionPartNumber
        enable-take-address=true, indirect-api=false, port=DataServices_DcmDspData_VM_CalibrationBaseline
        enable-take-address=true, indirect-api=false, port=DataServices_DcmDspData_VM_Specialdatabaseline
        enable-take-address=true, indirect-api=false, port=DataServices_DcmDspData_ReadFingerprint
        enable-take-address=true, indirect-api=false, port=DataServices_DcmDspData_ReadActiveDiagSession
        enable-take-address=true, indirect-api=false, port=DataServices_DcmDspData_VM_SparepartNumber
        enable-take-address=true, indirect-api=false, port=DataServices_DcmDspData_ECUDiagDatabaseVersion
        enable-take-address=true, indirect-api=false, port=DataServices_DcmDspData_BootloaderVersion
        enable-take-address=true, indirect-api=false, port=DataServices_DcmDspData_SystemSupplierIdData
        enable-take-address=true, indirect-api=false, port=DataServices_DcmDspData_ECUManufacturingDate
        enable-take-address=true, indirect-api=false, port=DataServices_DcmDspData_ECUSerialNumber
        enable-take-address=true, indirect-api=false, port=DataServices_DcmDspData_VIN
        enable-take-address=true, indirect-api=false, port=DataServices_DcmDspData_SystemName
        enable-take-address=true, indirect-api=false, port=DataServices_DcmDspData_RepairShopFingerPrint
        enable-take-address=true, indirect-api=false, port=DataServices_DcmDspData_ECUProgrammingDate
        enable-take-address=true, indirect-api=false, port=DataServices_DcmDspData_ECUConfigurarion
        enable-take-address=true, indirect-api=false, port=DataServices_DcmDspData_ConfigurarionFingerprint
        enable-take-address=true, indirect-api=false, port=SecurityAccess_Level_02
      7 x runnable:
        Dcm_MainFunction
          mode switch point ModeSwitchPointDcm_MainFunction_DcmControlDtcSetting_DcmControlDtcSetting: mode-group=DcmControlDtcSetting.DcmControlDtcSetting
          mode switch point ModeSwitchPointDcm_MainFunction_DcmEcuReset_DcmEcuReset: mode-group=DcmEcuReset.DcmEcuReset
          mode switch point ModeSwitchPointDcm_MainFunction_DcmDiagnosticSessionControl_DcmDiagnosticSessionControl: mode-group=DcmDiagnosticSessionControl.DcmDiagnosticSessionControl
          68 x sync call, all with timeout=0:
            OpServerCallDcm_MainFunction_GetSeed_SecurityAccess_Level_01: operation=SecurityAccess_Level_01.GetSeed
            OpServerCallDcm_MainFunction_CompareKey_SecurityAccess_Level_01: operation=SecurityAccess_Level_01.CompareKey
            OpServerCallDcm_MainFunction_ReadData_DataServices_Diag_RWDI_LightOnOffCounter_LightOnOffCounter_Value: operation=DataServices_Diag_RWDI_LightOnOffCounter_LightOnOffCounter_Value.ReadData
            OpServerCallDcm_MainFunction_ConditionCheckRead_DataServices_Diag_RWDI_LightOnOffCounter_LightOnOffCounter_Value: operation=DataServices_Diag_RWDI_LightOnOffCounter_LightOnOffCounter_Value.ConditionCheckRead
            OpServerCallDcm_MainFunction_WriteData_DataServices_Diag_RWDI_LightOnOffCounter_LightOnOffCounter_Value: operation=DataServices_Diag_RWDI_LightOnOffCounter_LightOnOffCounter_Value.WriteData
            OpServerCallDcm_MainFunction_ReadData_DataServices_Diag_VM_HardwarePartNumber: operation=DataServices_Diag_VM_HardwarePartNumber.ReadData
            OpServerCallDcm_MainFunction_ConditionCheckRead_DataServices_Diag_VM_HardwarePartNumber: operation=DataServices_Diag_VM_HardwarePartNumber.ConditionCheckRead
            OpServerCallDcm_MainFunction_WriteData_DataServices_Diag_VM_HardwarePartNumber: operation=DataServices_Diag_VM_HardwarePartNumber.WriteData
            OpServerCallDcm_MainFunction_ReadData_DataServices_Diag_VM_HardwareBaseline: operation=DataServices_Diag_VM_HardwareBaseline.ReadData
            OpServerCallDcm_MainFunction_ConditionCheckRead_DataServices_Diag_VM_HardwareBaseline: operation=DataServices_Diag_VM_HardwareBaseline.ConditionCheckRead
            OpServerCallDcm_MainFunction_WriteData_DataServices_Diag_VM_HardwareBaseline: operation=DataServices_Diag_VM_HardwareBaseline.WriteData
            OpServerCallDcm_MainFunction_ReadData_DataServices_DcmDspData_VM_SofwarePartNumber: operation=DataServices_DcmDspData_VM_SofwarePartNumber.ReadData
            OpServerCallDcm_MainFunction_ConditionCheckRead_DataServices_DcmDspData_VM_SofwarePartNumber: operation=DataServices_DcmDspData_VM_SofwarePartNumber.ConditionCheckRead
            OpServerCallDcm_MainFunction_WriteData_DataServices_DcmDspData_VM_SofwarePartNumber: operation=DataServices_DcmDspData_VM_SofwarePartNumber.WriteData
            OpServerCallDcm_MainFunction_ReadData_DataServices_DcmDspData_VM_SoftwarBaseline: operation=DataServices_DcmDspData_VM_SoftwarBaseline.ReadData
            OpServerCallDcm_MainFunction_ConditionCheckRead_DataServices_DcmDspData_VM_SoftwarBaseline: operation=DataServices_DcmDspData_VM_SoftwarBaseline.ConditionCheckRead
            OpServerCallDcm_MainFunction_WriteData_DataServices_DcmDspData_VM_SoftwarBaseline: operation=DataServices_DcmDspData_VM_SoftwarBaseline.WriteData
            OpServerCallDcm_MainFunction_ReadData_DataServices_DcmDspData_VM_FOTASpecialPartNumber: operation=DataServices_DcmDspData_VM_FOTASpecialPartNumber.ReadData
            OpServerCallDcm_MainFunction_ConditionCheckRead_DataServices_DcmDspData_VM_FOTASpecialPartNumber: operation=DataServices_DcmDspData_VM_FOTASpecialPartNumber.ConditionCheckRead
            OpServerCallDcm_MainFunction_WriteData_DataServices_DcmDspData_VM_FOTASpecialPartNumber: operation=DataServices_DcmDspData_VM_FOTASpecialPartNumber.WriteData
            OpServerCallDcm_MainFunction_ReadData_DataServices_DcmDspData_VM_CalibrarionPartNumber: operation=DataServices_DcmDspData_VM_CalibrarionPartNumber.ReadData
            OpServerCallDcm_MainFunction_ConditionCheckRead_DataServices_DcmDspData_VM_CalibrarionPartNumber: operation=DataServices_DcmDspData_VM_CalibrarionPartNumber.ConditionCheckRead
            OpServerCallDcm_MainFunction_WriteData_DataServices_DcmDspData_VM_CalibrarionPartNumber: operation=DataServices_DcmDspData_VM_CalibrarionPartNumber.WriteData
            OpServerCallDcm_MainFunction_ReadData_DataServices_DcmDspData_VM_CalibrationBaseline: operation=DataServices_DcmDspData_VM_CalibrationBaseline.ReadData
            OpServerCallDcm_MainFunction_ConditionCheckRead_DataServices_DcmDspData_VM_CalibrationBaseline: operation=DataServices_DcmDspData_VM_CalibrationBaseline.ConditionCheckRead
            OpServerCallDcm_MainFunction_WriteData_DataServices_DcmDspData_VM_CalibrationBaseline: operation=DataServices_DcmDspData_VM_CalibrationBaseline.WriteData
            OpServerCallDcm_MainFunction_ReadData_DataServices_DcmDspData_VM_Specialdatabaseline: operation=DataServices_DcmDspData_VM_Specialdatabaseline.ReadData
            OpServerCallDcm_MainFunction_ReadDataLength_DataServices_DcmDspData_VM_Specialdatabaseline: operation=DataServices_DcmDspData_VM_Specialdatabaseline.ReadDataLength
            OpServerCallDcm_MainFunction_ConditionCheckRead_DataServices_DcmDspData_VM_Specialdatabaseline: operation=DataServices_DcmDspData_VM_Specialdatabaseline.ConditionCheckRead
            OpServerCallDcm_MainFunction_WriteData_DataServices_DcmDspData_VM_Specialdatabaseline: operation=DataServices_DcmDspData_VM_Specialdatabaseline.WriteData
            OpServerCallDcm_MainFunction_ReadData_DataServices_DcmDspData_ReadFingerprint: operation=DataServices_DcmDspData_ReadFingerprint.ReadData
            OpServerCallDcm_MainFunction_ConditionCheckRead_DataServices_DcmDspData_ReadFingerprint: operation=DataServices_DcmDspData_ReadFingerprint.ConditionCheckRead
            OpServerCallDcm_MainFunction_ReadData_DataServices_DcmDspData_ReadActiveDiagSession: operation=DataServices_DcmDspData_ReadActiveDiagSession.ReadData
            OpServerCallDcm_MainFunction_ConditionCheckRead_DataServices_DcmDspData_ReadActiveDiagSession: operation=DataServices_DcmDspData_ReadActiveDiagSession.ConditionCheckRead
            OpServerCallDcm_MainFunction_ReadData_DataServices_DcmDspData_VM_SparepartNumber: operation=DataServices_DcmDspData_VM_SparepartNumber.ReadData
            OpServerCallDcm_MainFunction_ConditionCheckRead_DataServices_DcmDspData_VM_SparepartNumber: operation=DataServices_DcmDspData_VM_SparepartNumber.ConditionCheckRead
            OpServerCallDcm_MainFunction_WriteData_DataServices_DcmDspData_VM_SparepartNumber: operation=DataServices_DcmDspData_VM_SparepartNumber.WriteData
            OpServerCallDcm_MainFunction_ReadData_DataServices_DcmDspData_ECUDiagDatabaseVersion: operation=DataServices_DcmDspData_ECUDiagDatabaseVersion.ReadData
            OpServerCallDcm_MainFunction_ConditionCheckRead_DataServices_DcmDspData_ECUDiagDatabaseVersion: operation=DataServices_DcmDspData_ECUDiagDatabaseVersion.ConditionCheckRead
            OpServerCallDcm_MainFunction_ReadData_DataServices_DcmDspData_BootloaderVersion: operation=DataServices_DcmDspData_BootloaderVersion.ReadData
            OpServerCallDcm_MainFunction_ReadDataLength_DataServices_DcmDspData_BootloaderVersion: operation=DataServices_DcmDspData_BootloaderVersion.ReadDataLength
            OpServerCallDcm_MainFunction_ConditionCheckRead_DataServices_DcmDspData_BootloaderVersion: operation=DataServices_DcmDspData_BootloaderVersion.ConditionCheckRead
            OpServerCallDcm_MainFunction_ReadData_DataServices_DcmDspData_SystemSupplierIdData: operation=DataServices_DcmDspData_SystemSupplierIdData.ReadData
            OpServerCallDcm_MainFunction_ConditionCheckRead_DataServices_DcmDspData_SystemSupplierIdData: operation=DataServices_DcmDspData_SystemSupplierIdData.ConditionCheckRead
            OpServerCallDcm_MainFunction_ReadData_DataServices_DcmDspData_ECUManufacturingDate: operation=DataServices_DcmDspData_ECUManufacturingDate.ReadData
            OpServerCallDcm_MainFunction_ConditionCheckRead_DataServices_DcmDspData_ECUManufacturingDate: operation=DataServices_DcmDspData_ECUManufacturingDate.ConditionCheckRead
            OpServerCallDcm_MainFunction_ReadData_DataServices_DcmDspData_ECUSerialNumber: operation=DataServices_DcmDspData_ECUSerialNumber.ReadData
            OpServerCallDcm_MainFunction_ConditionCheckRead_DataServices_DcmDspData_ECUSerialNumber: operation=DataServices_DcmDspData_ECUSerialNumber.ConditionCheckRead
            OpServerCallDcm_MainFunction_ReadData_DataServices_DcmDspData_VIN: operation=DataServices_DcmDspData_VIN.ReadData
            OpServerCallDcm_MainFunction_ConditionCheckRead_DataServices_DcmDspData_VIN: operation=DataServices_DcmDspData_VIN.ConditionCheckRead
            OpServerCallDcm_MainFunction_WriteData_DataServices_DcmDspData_VIN: operation=DataServices_DcmDspData_VIN.WriteData
            OpServerCallDcm_MainFunction_ReadData_DataServices_DcmDspData_SystemName: operation=DataServices_DcmDspData_SystemName.ReadData
            OpServerCallDcm_MainFunction_ReadDataLength_DataServices_DcmDspData_SystemName: operation=DataServices_DcmDspData_SystemName.ReadDataLength
            OpServerCallDcm_MainFunction_ConditionCheckRead_DataServices_DcmDspData_SystemName: operation=DataServices_DcmDspData_SystemName.ConditionCheckRead
            OpServerCallDcm_MainFunction_ReadData_DataServices_DcmDspData_RepairShopFingerPrint: operation=DataServices_DcmDspData_RepairShopFingerPrint.ReadData
            OpServerCallDcm_MainFunction_ConditionCheckRead_DataServices_DcmDspData_RepairShopFingerPrint: operation=DataServices_DcmDspData_RepairShopFingerPrint.ConditionCheckRead
            OpServerCallDcm_MainFunction_WriteData_DataServices_DcmDspData_RepairShopFingerPrint: operation=DataServices_DcmDspData_RepairShopFingerPrint.WriteData
            OpServerCallDcm_MainFunction_ReadData_DataServices_DcmDspData_ECUProgrammingDate: operation=DataServices_DcmDspData_ECUProgrammingDate.ReadData
            OpServerCallDcm_MainFunction_ConditionCheckRead_DataServices_DcmDspData_ECUProgrammingDate: operation=DataServices_DcmDspData_ECUProgrammingDate.ConditionCheckRead
            OpServerCallDcm_MainFunction_ReadData_DataServices_DcmDspData_ECUConfigurarion: operation=DataServices_DcmDspData_ECUConfigurarion.ReadData
            OpServerCallDcm_MainFunction_ConditionCheckRead_DataServices_DcmDspData_ECUConfigurarion: operation=DataServices_DcmDspData_ECUConfigurarion.ConditionCheckRead
            OpServerCallDcm_MainFunction_WriteData_DataServices_DcmDspData_ECUConfigurarion: operation=DataServices_DcmDspData_ECUConfigurarion.WriteData
            OpServerCallDcm_MainFunction_ReadData_DataServices_DcmDspData_ConfigurarionFingerprint: operation=DataServices_DcmDspData_ConfigurarionFingerprint.ReadData
            OpServerCallDcm_MainFunction_ConditionCheckRead_DataServices_DcmDspData_ConfigurarionFingerprint: operation=DataServices_DcmDspData_ConfigurarionFingerprint.ConditionCheckRead
            OpServerCallDcm_MainFunction_WriteData_DataServices_DcmDspData_ConfigurarionFingerprint: operation=DataServices_DcmDspData_ConfigurarionFingerprint.WriteData
            OpServerCallDcm_MainFunction_GetSeed_SecurityAccess_Level_02: operation=SecurityAccess_Level_02.GetSeed
            OpServerCallDcm_MainFunction_CompareKey_SecurityAccess_Level_02: operation=SecurityAccess_Level_02.CompareKey
            OpServerCallDcm_MainFunction_WriteData_DataServices_DcmDspData_ECUDiagDatabaseVersion: operation=DataServices_DcmDspData_ECUDiagDatabaseVersion.WriteData
        GetActiveProtocol: can-be-invoked-concurrently=true, symbol=Dcm_GetActiveProtocol
        GetSesCtrlType: can-be-invoked-concurrently=true, symbol=Dcm_GetSesCtrlType
        ResetToDefaultSession: can-be-invoked-concurrently=true, symbol=Dcm_ResetToDefaultSession
        GetSecurityLevel: can-be-invoked-concurrently=true, symbol=Dcm_GetSecurityLevel
        SetActiveDiagnostic: can-be-invoked-concurrently=true, symbol=Dcm_SetActiveDiagnostic
        GetRequestKind: can-be-invoked-concurrently=true, symbol=Dcm_GetRequestKind
  swc implementation DcmImplementation: programming-language=C, behavior=DcmInternalBehavior
